# MK50D10 register map
Vendor: Freescale Semiconductor, Inc.; Series: Kinetis_K; File version: 1.6
CPU: CM4 r0p1, little endian, no MPU, no FPU, VTOR, 4 interrupt priority bits
Registers are 8-bit, read-write, reset 0x0 unless marked. A register's access mark holds for its fields unless they carry their own. Offsets are from the block's base; [hi:lo] are bit positions; {n}, {i} and the like mark numbered series; 'fields as' and 'values as' point back to an identical list.

## I2S0 — Inter-IC Sound / Synchronous Audio Interface
Base 0x4002F000; register names take the prefix I2S0_
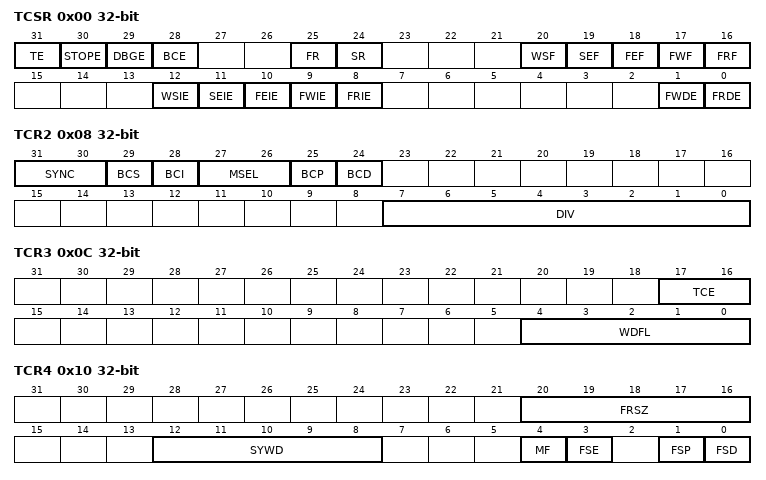
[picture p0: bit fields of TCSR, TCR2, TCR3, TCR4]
0x00 TCSR 32-bit — SAI Transmit Control Register
  [31] TE — Transmitter Enable
    0=Transmitter is disabled; 1=Transmitter is enabled, or transmitter has been disabled and has not yet reached end of frame
  [30] STOPE — Stop Enable
    0=Transmitter disabled in Stop mode; 1=Transmitter enabled in Stop mode
  [29] DBGE — Debug Enable
    0=Transmitter is disabled in Debug mode, after completing the current frame; 1=Transmitter is enabled in Debug mode
  [28] BCE — Bit Clock Enable
    0=Transmit bit clock is disabled; 1=Transmit bit clock is enabled
  [25] FR wo — FIFO Reset
    0=No effect; 1=FIFO reset
  [24] SR — Software Reset
    0=No effect; 1=Software reset
  [20] WSF — Word Start Flag
    0=Start of word not detected; 1=Start of word detected
  [19] SEF — Sync Error Flag
    0=Sync error not detected; 1=Frame sync error detected
  [18] FEF — FIFO Error Flag
    0=Transmit underrun not detected; 1=Transmit underrun detected
  [17] FWF ro — FIFO Warning Flag
    0=No enabled transmit FIFO is empty; 1=Enabled transmit FIFO is empty
  [16] FRF ro — FIFO Request Flag
    0=Transmit FIFO watermark has not been reached; 1=Transmit FIFO watermark has been reached
  [12] WSIE — Word Start Interrupt Enable
    0=Disables interrupt; 1=Enables interrupt
  [11] SEIE — Sync Error Interrupt Enable
    0=Disables interrupt; 1=Enables interrupt
  [10] FEIE — FIFO Error Interrupt Enable
    0=Disables the interrupt; 1=Enables the interrupt
  [9] FWIE — FIFO Warning Interrupt Enable
    0=Disables the interrupt; 1=Enables the interrupt
  [8] FRIE — FIFO Request Interrupt Enable
    0=Disables the interrupt; 1=Enables the interrupt
  [1] FWDE — FIFO Warning DMA Enable
    0=Disables the DMA request; 1=Enables the DMA request
  [0] FRDE — FIFO Request DMA Enable
    0=Disables the DMA request; 1=Enables the DMA request
0x04 TCR1 32-bit — SAI Transmit Configuration 1 Register
  [2:0] TFW — Transmit FIFO Watermark
0x08 TCR2 32-bit — SAI Transmit Configuration 2 Register
  [31:30] SYNC — Synchronous Mode
    0=Asynchronous mode; 1=Synchronous with receiver; 2=Synchronous with another SAI transmitter; 3=Synchronous with another SAI receiver
  [29] BCS — Bit Clock Swap
    0=Use the normal bit clock source; 1=Swap the bit clock source
  [28] BCI — Bit Clock Input
    0=No effect; 1=Internal logic is clocked as if bit clock was externally generated
  [27:26] MSEL — MCLK Select
    0=Bus Clock selected; 1=Master Clock 1 selected; 2=Master Clock 2 selected; 3=Master Clock 3 selected
  [25] BCP — Bit Clock Polarity
    0=Bit clock is active high with drive outputs on rising edge and sample inputs on falling edge; 1=Bit clock is active low with drive outputs on falling edge and sample inputs on rising edge
  [24] BCD — Bit Clock Direction
    0=Bit clock is generated externally in Slave mode; 1=Bit clock is generated internally in Master mode
  [7:0] DIV — Bit Clock Divide
0x0C TCR3 32-bit — SAI Transmit Configuration 3 Register
  [17:16] TCE — Transmit Channel Enable
    0=Transmit data channel N is disabled; 1=Transmit data channel N is enabled
  [4:0] WDFL — Word Flag Configuration
0x10 TCR4 32-bit — SAI Transmit Configuration 4 Register
  [20:16] FRSZ — Frame size
  [12:8] SYWD — Sync Width
  [4] MF — MSB First
    0=LSB is transmitted first; 1=MSB is transmitted first
  [3] FSE — Frame Sync Early
    0=Frame sync asserts with the first bit of the frame; 1=Frame sync asserts one bit before the first bit of the frame
  [1] FSP — Frame Sync Polarity
    0=Frame sync is active high; 1=Frame sync is active low
  [0] FSD — Frame Sync Direction
    0=Frame sync is generated externally in Slave mode; 1=Frame sync is generated internally in Master mode
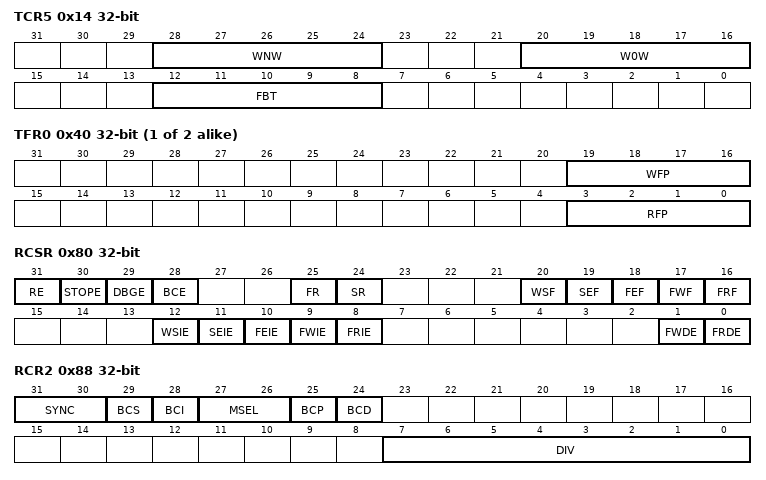
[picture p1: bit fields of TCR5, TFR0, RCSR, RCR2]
0x14 TCR5 32-bit — SAI Transmit Configuration 5 Register
  [28:24] WNW — Word N Width
  [20:16] W0W — Word 0 Width
  [12:8] FBT — First Bit Shifted
{0x20+4i} TDR{i} (i=0..1) 32-bit wo — SAI Transmit Data Register
  [31:0] TDR — Transmit Data Register
{0x40+4i} TFR{i} (i=0..1) 32-bit ro — SAI Transmit FIFO Register
  [19:16] WFP — Write FIFO Pointer
  [3:0] RFP — Read FIFO Pointer
0x60 TMR 32-bit — SAI Transmit Mask Register
  [31:0] TWM — Transmit Word Mask
    0=Word N is enabled; 1=Word N is masked. The transmit data pins are tri-stated when masked.
0x80 RCSR 32-bit — SAI Receive Control Register
  [31] RE — Receiver Enable
    0=Receiver is disabled; 1=Receiver is enabled, or receiver has been disabled and has not yet reached end of frame
  [30] STOPE — Stop Enable
    0=Receiver disabled in Stop mode; 1=Receiver enabled in Stop mode
  [29] DBGE — Debug Enable
    0=Receiver is disabled in Debug mode, after completing the current frame; 1=Receiver is enabled in Debug mode
  [28] BCE — Bit Clock Enable
    0=Receive bit clock is disabled; 1=Receive bit clock is enabled
  [25] FR wo — FIFO Reset
    0=No effect; 1=FIFO reset
  [24] SR — Software Reset
    0=No effect; 1=Software reset
  [20] WSF — Word Start Flag
    0=Start of word not detected; 1=Start of word detected
  [19] SEF — Sync Error Flag
    0=Sync error not detected; 1=Frame sync error detected
  [18] FEF — FIFO Error Flag
    0=Receive overflow not detected; 1=Receive overflow detected
  [17] FWF ro — FIFO Warning Flag
    0=No enabled receive FIFO is full; 1=Enabled receive FIFO is full
  [16] FRF ro — FIFO Request Flag
    0=Receive FIFO watermark not reached; 1=Receive FIFO watermark has been reached
  [12] WSIE — Word Start Interrupt Enable
    0=Disables interrupt; 1=Enables interrupt
  [11] SEIE — Sync Error Interrupt Enable
    0=Disables interrupt; 1=Enables interrupt
  [10] FEIE — FIFO Error Interrupt Enable
    0=Disables the interrupt; 1=Enables the interrupt
  [9] FWIE — FIFO Warning Interrupt Enable
    0=Disables the interrupt; 1=Enables the interrupt
  [8] FRIE — FIFO Request Interrupt Enable
    0=Disables the interrupt; 1=Enables the interrupt
  [1] FWDE — FIFO Warning DMA Enable
    0=Disables the DMA request; 1=Enables the DMA request
  [0] FRDE — FIFO Request DMA Enable
    0=Disables the DMA request; 1=Enables the DMA request
0x84 RCR1 32-bit — SAI Receive Configuration 1 Register
  [2:0] RFW — Receive FIFO Watermark
0x88 RCR2 32-bit — SAI Receive Configuration 2 Register
  [31:30] SYNC — Synchronous Mode
    0=Asynchronous mode; 1=Synchronous with transmitter; 2=Synchronous with another SAI receiver; 3=Synchronous with another SAI transmitter
  [29] BCS — Bit Clock Swap
    values as TCR2.BCS
  [28] BCI — Bit Clock Input
    values as TCR2.BCI
  [27:26] MSEL — MCLK Select
    0=Bus clock selected; 1=Master clock 1 selected; 2=Master clock 2 selected; 3=Master clock 3 selected
  [25] BCP — Bit Clock Polarity
    0=Bit Clock is active high with drive outputs on rising edge and sample inputs on falling edge; 1=Bit Clock is active low with drive outputs on falling edge and sample inputs on rising edge
  [24] BCD — Bit Clock Direction
    values as TCR2.BCD
  [7:0] DIV — Bit Clock Divide
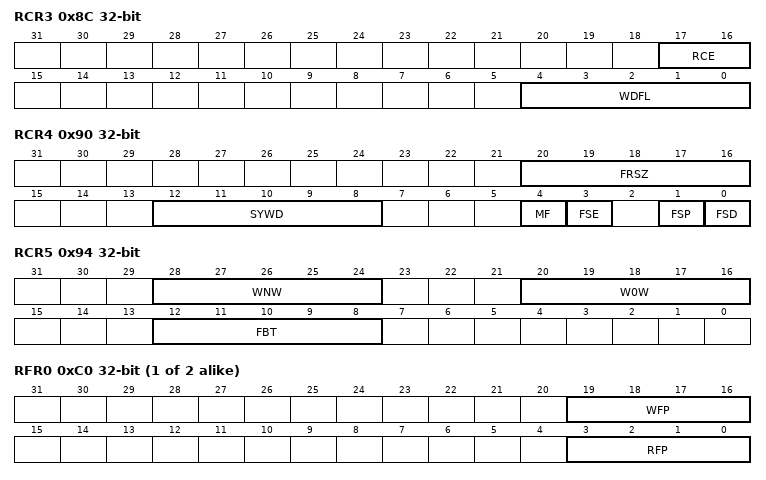
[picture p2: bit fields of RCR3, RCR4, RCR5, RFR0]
0x8C RCR3 32-bit — SAI Receive Configuration 3 Register
  [17:16] RCE — Receive Channel Enable
    0=Receive data channel N is disabled; 1=Receive data channel N is enabled
  [4:0] WDFL — Word Flag Configuration
0x90 RCR4 32-bit — SAI Receive Configuration 4 Register
  [20:16] FRSZ — Frame Size
  [12:8] SYWD — Sync Width
  [4] MF — MSB First
    0=LSB is received first; 1=MSB is received first
  [3] FSE — Frame Sync Early
    values as TCR4.FSE
  [1] FSP — Frame Sync Polarity
    0=Frame sync is active high; 1=Frame sync is active low
  [0] FSD — Frame Sync Direction
    0=Frame Sync is generated externally in Slave mode; 1=Frame Sync is generated internally in Master mode
0x94 RCR5 32-bit — SAI Receive Configuration 5 Register
  fields as TCR5
{0xA0+4i} RDR{i} (i=0..1) 32-bit ro — SAI Receive Data Register
  [31:0] RDR — Receive Data Register
{0xC0+4i} RFR{i} (i=0..1) 32-bit ro — SAI Receive FIFO Register
  [19:16] WFP — Write FIFO Pointer
  [3:0] RFP — Read FIFO Pointer
0xE0 RMR 32-bit — SAI Receive Mask Register
  [31:0] RWM — Receive Word Mask
    0=Word N is enabled; 1=Word N is masked
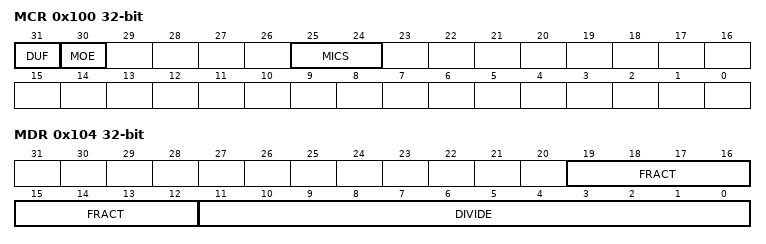
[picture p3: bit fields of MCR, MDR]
0x100 MCR 32-bit — SAI MCLK Control Register
  [31] DUF ro — Divider Update Flag
    0=MCLK divider ratio is not being updated currently; 1=MCLK divider ratio is updating on-the-fly. Further updates to the MCLK divider ratio are blocked while this flag remains set.
  [30] MOE — MCLK Output Enable
    0=MCLK signal pin is configured as an input that bypasses the MCLK divider; 1=MCLK signal pin is configured as an output from the MCLK divider and the MCLK divider is enabled
  [25:24] MICS — MCLK Input Clock Select
    {v}=MCLK divider input clock {v} selected (v=0..3)
0x104 MDR 32-bit — SAI MCLK Divide Register
  [19:12] FRACT — MCLK Fraction
  [11:0] DIVIDE — MCLK Divide
